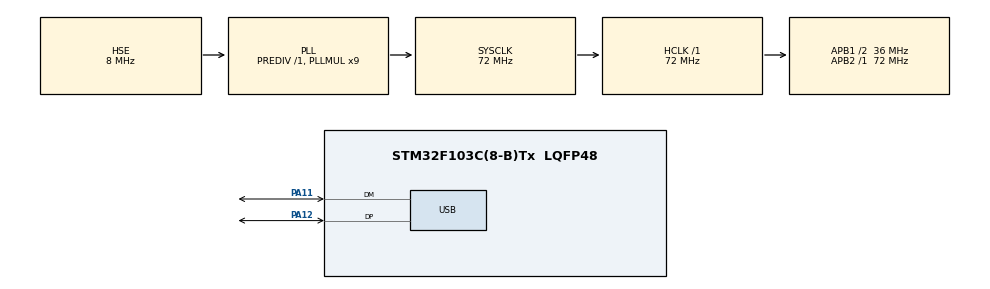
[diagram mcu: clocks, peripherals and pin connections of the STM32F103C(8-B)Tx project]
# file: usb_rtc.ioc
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Mcu.Family=STM32F1
Mcu.Name=STM32F103C(8-B)Tx
Mcu.Package=LQFP48
NVIC.PriorityGroup=NVIC_PRIORITYGROUP_4
NVIC.USB_LP_CAN1_RX0_IRQn=true\:0\:0\:false\:false\:true\:false\:true
PA11.Mode=Device
PA11.Signal=USB_DM
PA12.Mode=Device
PA12.Signal=USB_DP
PA13.Mode=Serial_Wire
PA13.Signal=SYS_JTMS-SWDIO
PA14.Mode=Serial_Wire
PA14.Signal=SYS_JTCK-SWCLK
PC14-OSC32_IN.Mode=LSE-External-Oscillator
PC14-OSC32_IN.Signal=RCC_OSC32_IN
PC15-OSC32_OUT.Mode=LSE-External-Oscillator
PC15-OSC32_OUT.Signal=RCC_OSC32_OUT
PD0-OSC_IN.Mode=HSE-External-Oscillator
PD0-OSC_IN.Signal=RCC_OSC_IN
PD1-OSC_OUT.Mode=HSE-External-Oscillator
PD1-OSC_OUT.Signal=RCC_OSC_OUT
ProjectManager.HeapSize=0x200
ProjectManager.StackSize=0x400
ProjectManager.TargetToolchain=TrueSTUDIO
RCC.AHBFreq_Value=72000000
RCC.APB1CLKDivider=RCC_HCLK_DIV2
RCC.APB1Freq_Value=36000000
RCC.APB1TimFreq_Value=72000000
RCC.APB2Freq_Value=72000000
RCC.APB2TimFreq_Value=72000000
RCC.HCLKFreq_Value=72000000
RCC.PLLMUL=RCC_PLL_MUL9
RCC.PLLSourceVirtual=RCC_PLLSOURCE_HSE
RCC.RTCClockSelection=RCC_RTCCLKSOURCE_LSE
RCC.SYSCLKFreq_VALUE=72000000
RCC.SYSCLKSource=RCC_SYSCLKSOURCE_PLLCLK
RCC.USBFreq_Value=48000000
RCC.USBPrescaler=RCC_USBCLKSOURCE_PLL_DIV1_5
RTC.Date=30
RTC.Format=RTC_FORMAT_BIN
RTC.Minutes=16
RTC.Month=RTC_MONTH_MAY
RTC.Year=19
USB_DEVICE.CLASS_NAME_FS=CDC
USB_DEVICE.VirtualMode=Cdc
USB_DEVICE.VirtualModeFS=Cdc_FS
VP_RTC_VS_RTC_Activate.Mode=RTC_Enabled
VP_RTC_VS_RTC_Calendar.Mode=RTC_Calendar
VP_USB_DEVICE_VS_USB_DEVICE_CDC_FS.Mode=CDC_FS
board=custom

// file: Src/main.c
/* USER CODE BEGIN Header */
/**
  ******************************************************************************
  * @file           : main.c
  * @brief          : Main program body
  ******************************************************************************
  * @attention
  *
  * <h2><center>&copy; Copyright (c) 2019 STMicroelectronics.
  * All rights reserved.</center></h2>
  *
  * This software component is licensed by ST under Ultimate Liberty license
  * SLA0044, the "License"; You may not use this file except in compliance with
  * the License. You may obtain a copy of the License at:
  *                             www.st.com/SLA0044
  *
  ******************************************************************************
  */
/* USER CODE END Header */

#include "main.h"
#include "usb_device.h"

/* USER CODE BEGIN Includes */
#include "string.h"
#include "usbd_cdc_if.h"
/* USER CODE END Includes */

RTC_HandleTypeDef hrtc;

/* USER CODE BEGIN PV */
extern USBD_HandleTypeDef hUsbDeviceFS;
/* USER CODE END PV */

void SystemClock_Config(void);
static void MX_GPIO_Init(void);
static void MX_RTC_Init(void);
/* USER CODE BEGIN PFP */
void USB_Reset(void);
/* USER CODE END PFP */

int main(void)
{

  /* MCU Configuration--------------------------------------------------------*/

  /* Reset of all peripherals, Initializes the Flash interface and the Systick. */
  HAL_Init();

  /* Configure the system clock */
  SystemClock_Config();

  /* Initialize all configured peripherals */
  MX_GPIO_Init();
  MX_RTC_Init();
  MX_USB_DEVICE_Init();
  /* USER CODE BEGIN 2 */

  // После перегенерации в Кубе добавить USB_Reset(); в функцию MX_GPIO_Init(void) (после ...CLK_ENABLE(); )

  RTC_TimeTypeDef sTime = {0};
  RTC_DateTypeDef DateToUpdate = {0};
  char trans_str[128] = {0,};
  /* USER CODE END 2 */

  /* Infinite loop */
  /* USER CODE BEGIN WHILE */
  while (1)
  {
	    HAL_RTC_GetTime(&hrtc, &sTime, RTC_FORMAT_BIN); // RTC_FORMAT_BIN , RTC_FORMAT_BCD
	    HAL_RTC_GetDate(&hrtc, &DateToUpdate, RTC_FORMAT_BIN);
		snprintf(trans_str, 128, "Time %d:%d:%d\nDate %d-%d-20%d\n", sTime.Hours, sTime.Minutes, sTime.Seconds, DateToUpdate.Date, DateToUpdate.Month, DateToUpdate.Year);
		CDC_Transmit_FS((uint8_t*)trans_str, strlen(trans_str));

		HAL_Delay(1000);

    /* USER CODE END WHILE */

  }
}

void SystemClock_Config(void)
{
  RCC_OscInitTypeDef RCC_OscInitStruct = {0};
  RCC_ClkInitTypeDef RCC_ClkInitStruct = {0};
  RCC_PeriphCLKInitTypeDef PeriphClkInit = {0};

  /** Initializes the CPU, AHB and APB busses clocks
  */
  RCC_OscInitStruct.OscillatorType = RCC_OSCILLATORTYPE_HSE|RCC_OSCILLATORTYPE_LSE;
  RCC_OscInitStruct.HSEState = RCC_HSE_ON;
  RCC_OscInitStruct.HSEPredivValue = RCC_HSE_PREDIV_DIV1;
  RCC_OscInitStruct.LSEState = RCC_LSE_ON;
  RCC_OscInitStruct.HSIState = RCC_HSI_ON;
  RCC_OscInitStruct.PLL.PLLState = RCC_PLL_ON;
  RCC_OscInitStruct.PLL.PLLSource = RCC_PLLSOURCE_HSE;
  RCC_OscInitStruct.PLL.PLLMUL = RCC_PLL_MUL9;
  if (HAL_RCC_OscConfig(&RCC_OscInitStruct) != HAL_OK)
  {
    Error_Handler();
  }
  /** Initializes the CPU, AHB and APB busses clocks
  */
  RCC_ClkInitStruct.ClockType = RCC_CLOCKTYPE_HCLK|RCC_CLOCKTYPE_SYSCLK
                              |RCC_CLOCKTYPE_PCLK1|RCC_CLOCKTYPE_PCLK2;
  RCC_ClkInitStruct.SYSCLKSource = RCC_SYSCLKSOURCE_PLLCLK;
  RCC_ClkInitStruct.AHBCLKDivider = RCC_SYSCLK_DIV1;
  RCC_ClkInitStruct.APB1CLKDivider = RCC_HCLK_DIV2;
  RCC_ClkInitStruct.APB2CLKDivider = RCC_HCLK_DIV1;

  if (HAL_RCC_ClockConfig(&RCC_ClkInitStruct, FLASH_LATENCY_2) != HAL_OK)
  {
    Error_Handler();
  }
  PeriphClkInit.PeriphClockSelection = RCC_PERIPHCLK_RTC|RCC_PERIPHCLK_USB;
  PeriphClkInit.RTCClockSelection = RCC_RTCCLKSOURCE_LSE;
  PeriphClkInit.UsbClockSelection = RCC_USBCLKSOURCE_PLL_DIV1_5;
  if (HAL_RCCEx_PeriphCLKConfig(&PeriphClkInit) != HAL_OK)
  {
    Error_Handler();
  }
}

static void MX_RTC_Init(void)
{

  RTC_TimeTypeDef sTime = {0};
  RTC_DateTypeDef DateToUpdate = {0};

  /** Initialize RTC Only
  */
  hrtc.Instance = RTC;
  hrtc.Init.AsynchPrediv = RTC_AUTO_1_SECOND;
  hrtc.Init.OutPut = RTC_OUTPUTSOURCE_ALARM;
  if (HAL_RTC_Init(&hrtc) != HAL_OK)
  {
    Error_Handler();
  }

  /** Initialize RTC and set the Time and Date
  */
  sTime.Hours = 0;
  sTime.Minutes = 16;
  sTime.Seconds = 0;

  if (HAL_RTC_SetTime(&hrtc, &sTime, RTC_FORMAT_BIN) != HAL_OK)
  {
    Error_Handler();
  }
  DateToUpdate.WeekDay = RTC_WEEKDAY_MONDAY;
  DateToUpdate.Month = RTC_MONTH_MAY;
  DateToUpdate.Date = 30;
  DateToUpdate.Year = 19;

  if (HAL_RTC_SetDate(&hrtc, &DateToUpdate, RTC_FORMAT_BIN) != HAL_OK)
  {
    Error_Handler();
  }

}

static void MX_GPIO_Init(void)
{

  /* GPIO Ports Clock Enable */
  __HAL_RCC_GPIOC_CLK_ENABLE();
  __HAL_RCC_GPIOD_CLK_ENABLE();
  __HAL_RCC_GPIOA_CLK_ENABLE();

  USB_Reset();

}

/* USER CODE BEGIN 4 */
// После перегенерации в Кубе добавить USB_Reset(); в функцию MX_GPIO_Init(void) (после ...CLK_ENABLE(); )

void USB_Reset(void)
{

	 GPIO_InitTypeDef GPIO_InitStruct = {0};

	 // инициализируем пин DP как выход
	 GPIO_InitStruct.Pin = GPIO_PIN_12;
	 GPIO_InitStruct.Mode = GPIO_MODE_OUTPUT_PP;
	 GPIO_InitStruct.Speed = GPIO_SPEED_FREQ_LOW;
	 HAL_GPIO_Init(GPIOA, &GPIO_InitStruct);
	 HAL_GPIO_WritePin(GPIOA, GPIO_PIN_12, GPIO_PIN_RESET); // прижимаем DP к "земле"
	 for(uint16_t i = 0; i < 2000; i++) {}; // немного ждём

	 // переинициализируем пин для работы с USB
	 GPIO_InitStruct.Mode = GPIO_MODE_INPUT;
	 GPIO_InitStruct.Pull = GPIO_NOPULL;
	 HAL_GPIO_Init(GPIOA, &GPIO_InitStruct);
	 for(uint16_t i = 0; i < 2000; i++) {}; // немного ждём
}
/* USER CODE END 4 */

void Error_Handler(void)
{
}

/************************ (C) COPYRIGHT STMicroelectronics *****END OF FILE****/
